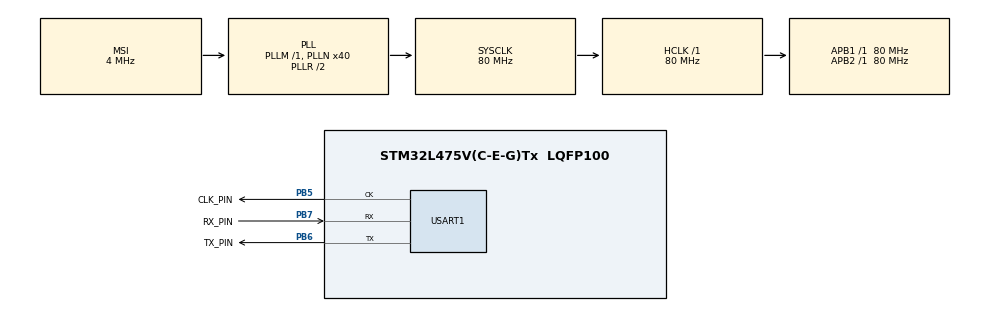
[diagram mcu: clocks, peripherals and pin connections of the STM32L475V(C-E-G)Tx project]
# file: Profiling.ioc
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Mcu.Family=STM32L4
Mcu.Name=STM32L475V(C-E-G)Tx
Mcu.Package=LQFP100
NVIC.PriorityGroup=NVIC_PRIORITYGROUP_4
PB5.GPIO_Label=CLK_PIN
PB5.Mode=Synchronous
PB5.Signal=USART1_CK
PB6.GPIO_Label=TX_PIN
PB6.Mode=Synchronous
PB6.Signal=USART1_TX
PB7.GPIO_Label=RX_PIN
PB7.Mode=Synchronous
PB7.Signal=USART1_RX
ProjectManager.HeapSize=0x2000
ProjectManager.StackSize=0x4000
ProjectManager.TargetToolchain=MDK-ARM V5
RCC.ADCFreq_Value=48000000
RCC.AHBFreq_Value=80000000
RCC.APB1Freq_Value=80000000
RCC.APB1TimFreq_Value=80000000
RCC.APB2Freq_Value=80000000
RCC.APB2TimFreq_Value=80000000
RCC.CortexFreq_Value=80000000
RCC.HCLKFreq_Value=80000000
RCC.HSE_VALUE=8000000
RCC.HSI_VALUE=16000000
RCC.LSE_VALUE=32768
RCC.MSI_VALUE=4000000
RCC.PLLN=40
RCC.PLLSAI1N=24
RCC.SYSCLKFreq_VALUE=80000000
RCC.SYSCLKSource=RCC_SYSCLKSOURCE_PLLCLK
RCC.USBFreq_Value=48000000
RCC.VCOOutputFreq_Value=160000000
USART1.VirtualMode-Synchronous=VM_SYNC
board=B-L475E-IOT01A

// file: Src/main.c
/* USER CODE BEGIN Header */
/**
  ******************************************************************************
  * @file           : main.c
  * @brief          : Main program body
  ******************************************************************************
  * @attention
  *
  * <h2><center>&copy; Copyright (c) 2019 STMicroelectronics.
  * All rights reserved.</center></h2>
  *
  * This software component is licensed by ST under BSD 3-Clause license,
  * the "License"; You may not use this file except in compliance with the
  * License. You may obtain a copy of the License at:
  *                        opensource.org/licenses/BSD-3-Clause
  *
  ******************************************************************************
  */
/* USER CODE END Header */

#include "main.h"

/* USER CODE BEGIN Includes */
#include <stdio.h>
#include <stdlib.h>
#include <arm_math.h>
#include "CycleCounter.h"

/* USER CODE END Includes */

/* USER CODE BEGIN PTD */

#include "nnom.h"
#include "weights.h"

/* USER CODE END PTD */

USART_HandleTypeDef husart1;

void SystemClock_Config(void);
static void MX_GPIO_Init(void);
static void MX_USART1_Init(void);

/* USER CODE BEGIN PFP */

#ifdef __GNUC__
/* With GCC/RAISONANCE, small msg_info (option LD Linker->Libraries->Small msg_info
   set to 'Yes') calls __io_putchar() */
#define PUTCHAR_PROTOTYPE int __io_putchar(int ch)
#define GETCHAR_PROTOTYPE int __io_getchar(void)
#else
#define PUTCHAR_PROTOTYPE int fputc(int ch, FILE *f)
#define GETCHAR_PROTOTYPE int fgetc(FILE *f)
#endif /* __GNUC__ */

/* USER CODE END PFP */

/* USER CODE BEGIN 0 */
PUTCHAR_PROTOTYPE {
  while (HAL_OK != HAL_USART_Transmit(&husart1, (uint8_t *) &ch, 1, 30000)){;}
  return ch;
}

GETCHAR_PROTOTYPE {
 uint8_t ch = 0;
  while (HAL_OK != HAL_USART_Receive(&husart1, (uint8_t *)&ch, 1, 30000)){;}
  return ch;
}
/* USER CODE END 0 */

int main(void)
{
	__disable_irq();

  /* MCU Configuration--------------------------------------------------------*/

  /* Reset of all peripherals, Initializes the Flash interface and the Systick. */
  HAL_Init();

  /* Configure the system clock */
  SystemClock_Config();
	__HAL_FLASH_SET_LATENCY(1);

  /* Initialize all configured peripherals */
  MX_GPIO_Init();
  MX_USART1_Init();
  /* USER CODE BEGIN 2 */

	printf("NNoM benchmark\r\n");

	nnom_model_t* model;
	model = nnom_model_create();

	uint8_t* test_data = (uint8_t*) calloc(156*13, sizeof(uint8_t));

	memcpy(nnom_input_data, test_data, 156*13);

	uint32_t pred_label;
	float probability;
	ResetTimer();
	StartTimer();
	nnom_predict(model, &pred_label, &probability);
	StopTimer();

	printf("Predicted label was %i, with %f percent confidence, took %i cycles \r\n",pred_label,probability*100,getCycles());

  /* USER CODE END 2 */

  /* Infinite loop */
  while (1)
  {
  }
}

void SystemClock_Config(void)
{
  RCC_OscInitTypeDef RCC_OscInitStruct = {0};
  RCC_ClkInitTypeDef RCC_ClkInitStruct = {0};
  RCC_PeriphCLKInitTypeDef PeriphClkInit = {0};

  /** Initializes the CPU, AHB and APB busses clocks
  */
  RCC_OscInitStruct.OscillatorType = RCC_OSCILLATORTYPE_MSI;
  RCC_OscInitStruct.MSIState = RCC_MSI_ON;
  RCC_OscInitStruct.MSICalibrationValue = 0;
  RCC_OscInitStruct.MSIClockRange = RCC_MSIRANGE_6;
  RCC_OscInitStruct.PLL.PLLState = RCC_PLL_ON;
  RCC_OscInitStruct.PLL.PLLSource = RCC_PLLSOURCE_MSI;
  RCC_OscInitStruct.PLL.PLLM = 1;
  RCC_OscInitStruct.PLL.PLLN = 40;
  RCC_OscInitStruct.PLL.PLLP = RCC_PLLP_DIV7;
  RCC_OscInitStruct.PLL.PLLQ = RCC_PLLQ_DIV2;
  RCC_OscInitStruct.PLL.PLLR = RCC_PLLR_DIV2;
  if (HAL_RCC_OscConfig(&RCC_OscInitStruct) != HAL_OK)
  {
    Error_Handler();
  }
  /** Initializes the CPU, AHB and APB busses clocks
  */
  RCC_ClkInitStruct.ClockType = RCC_CLOCKTYPE_HCLK|RCC_CLOCKTYPE_SYSCLK
                              |RCC_CLOCKTYPE_PCLK1|RCC_CLOCKTYPE_PCLK2;
  RCC_ClkInitStruct.SYSCLKSource = RCC_SYSCLKSOURCE_PLLCLK;
  RCC_ClkInitStruct.AHBCLKDivider = RCC_SYSCLK_DIV1;
  RCC_ClkInitStruct.APB1CLKDivider = RCC_HCLK_DIV1;
  RCC_ClkInitStruct.APB2CLKDivider = RCC_HCLK_DIV1;

  if (HAL_RCC_ClockConfig(&RCC_ClkInitStruct, FLASH_LATENCY_4) != HAL_OK)
  {
    Error_Handler();
  }
  PeriphClkInit.PeriphClockSelection = RCC_PERIPHCLK_USART1;
  PeriphClkInit.Usart1ClockSelection = RCC_USART1CLKSOURCE_PCLK2;
  if (HAL_RCCEx_PeriphCLKConfig(&PeriphClkInit) != HAL_OK)
  {
    Error_Handler();
  }
  /** Configure the main internal regulator output voltage
  */
  if (HAL_PWREx_ControlVoltageScaling(PWR_REGULATOR_VOLTAGE_SCALE1) != HAL_OK)
  {
    Error_Handler();
  }
}

static void MX_USART1_Init(void)
{

  husart1.Instance = USART1;
  husart1.Init.BaudRate = 115200;
  husart1.Init.WordLength = USART_WORDLENGTH_8B;
  husart1.Init.StopBits = USART_STOPBITS_1;
  husart1.Init.Parity = USART_PARITY_NONE;
  husart1.Init.Mode = USART_MODE_TX_RX;
  husart1.Init.CLKPolarity = USART_POLARITY_LOW;
  husart1.Init.CLKPhase = USART_PHASE_1EDGE;
  husart1.Init.CLKLastBit = USART_LASTBIT_DISABLE;
  if (HAL_USART_Init(&husart1) != HAL_OK)
  {
    Error_Handler();
  }

}

static void MX_GPIO_Init(void)
{

  /* GPIO Ports Clock Enable */
  __HAL_RCC_GPIOB_CLK_ENABLE();

}

void Error_Handler(void)
{
}

/************************ (C) COPYRIGHT STMicroelectronics *****END OF FILE****/
